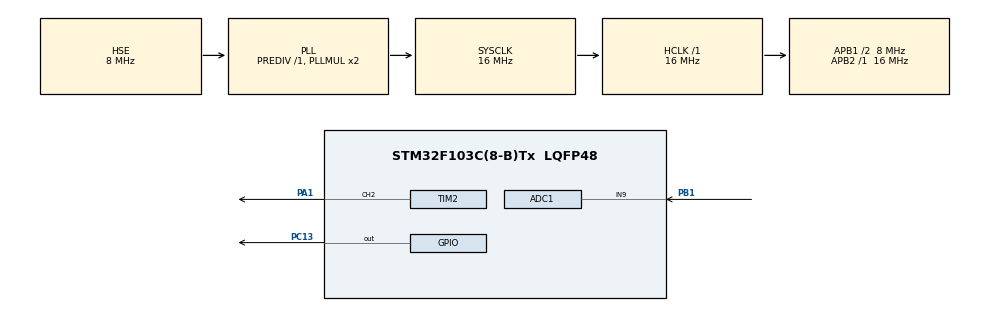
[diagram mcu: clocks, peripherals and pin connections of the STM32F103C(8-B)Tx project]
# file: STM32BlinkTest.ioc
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ADC1.Channel-1\#ChannelRegularConversion=ADC_CHANNEL_9
ADC1.ContinuousConvMode=ENABLE
ADC1.NbrOfConversionFlag=1
ADC1.Rank-1\#ChannelRegularConversion=1
ADC1.SamplingTime-1\#ChannelRegularConversion=ADC_SAMPLETIME_1CYCLE_5
ADC1.master=1
Mcu.Family=STM32F1
Mcu.Name=STM32F103C(8-B)Tx
Mcu.Package=LQFP48
NVIC.PriorityGroup=NVIC_PRIORITYGROUP_4
PA1.Signal=S_TIM2_CH2
PA13.Mode=Serial_Wire
PA13.Signal=SYS_JTMS-SWDIO
PA14.Mode=Serial_Wire
PA14.Signal=SYS_JTCK-SWCLK
PB1.Signal=ADCx_IN9
PC13-TAMPER-RTC.Signal=GPIO_Output
PD0-OSC_IN.Mode=HSE-External-Oscillator
PD0-OSC_IN.Signal=RCC_OSC_IN
PD1-OSC_OUT.Mode=HSE-External-Oscillator
PD1-OSC_OUT.Signal=RCC_OSC_OUT
ProjectManager.HeapSize=0x200
ProjectManager.StackSize=0x400
ProjectManager.TargetToolchain=STM32CubeIDE
RCC.AHBFreq_Value=16000000
RCC.APB1CLKDivider=RCC_HCLK_DIV2
RCC.APB1Freq_Value=8000000
RCC.APB1TimFreq_Value=16000000
RCC.APB2Freq_Value=16000000
RCC.APB2TimFreq_Value=16000000
RCC.HCLKFreq_Value=16000000
RCC.PLLSourceVirtual=RCC_PLLSOURCE_HSE
RCC.SYSCLKFreq_VALUE=16000000
RCC.SYSCLKSource=RCC_SYSCLKSOURCE_PLLCLK
RCC.USBFreq_Value=16000000
SH.ADCx_IN9.0=ADC1_IN9,IN9
SH.S_TIM2_CH2.0=TIM2_CH2,PWM Generation2 CH2
TIM2.Channel-PWM\ Generation2\ CH2=TIM_CHANNEL_2
TIM2.Period=625
TIM2.Prescaler=127
VP_TIM2_VS_ClockSourceINT.Mode=Internal
board=custom

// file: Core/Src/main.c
/* USER CODE BEGIN Header */
/**
  ******************************************************************************
  * @file           : main.c
  * @brief          : Main program body
  ******************************************************************************
  * @attention
  *
  * Copyright (c) 2023 STMicroelectronics.
  * All rights reserved.
  *
  * This software is licensed under terms that can be found in the LICENSE file
  * in the root directory of this software component.
  * If no LICENSE file comes with this software, it is provided AS-IS.
  *
  ******************************************************************************
  */
/* USER CODE END Header */
#include "main.h"
#include "adc.h"
#include "tim.h"
#include "gpio.h"

/* USER CODE BEGIN Includes */
//TIM_HandleTypeDef htim2;
/* USER CODE END Includes */

void SystemClock_Config(void);

int main(void)
{
  /* USER CODE BEGIN 1 */
//	int32_t CH_DC = 0;
  /* USER CODE END 1 */

  /* MCU Configuration--------------------------------------------------------*/

  /* Reset of all peripherals, Initializes the Flash interface and the Systick. */
  HAL_Init();

  /* Configure the system clock */
  SystemClock_Config();

  /* Initialize all configured peripherals */
  MX_GPIO_Init();
  MX_TIM2_Init();
  MX_ADC1_Init();
  /* USER CODE BEGIN 2 */
//  HAL_TIM_PWM_Start(&htim2, TIM_CHANNEL_2);
//  int32_t CH1_DC = 0;

  uint16_t readValue;
  HAL_ADC_Start(&hadc1);
  /* USER CODE END 2 */

  /* Infinite loop */
  while (1)
  {

    /* USER CODE BEGIN 3 */

//	  HAL_GPIO_TogglePin(GPIOC, GPIO_PIN_13);

//	  HAL_Delay(3000);
//	  HAL_GPIO_WritePin(GPIOB, GPIO_PIN_5, GPIO_PIN_SET);
//	  GPIO_PinState state = HAL_GPIO_ReadPin(GPIOB, GPIO_PIN_6);
//	  if (state) {
//		  HAL_GPIO_WritePin(GPIOC, GPIO_PIN_13, GPIO_PIN_SET);
//
//	  }
//	  else {
//		  HAL_GPIO_WritePin(GPIOC, GPIO_PIN_13, GPIO_PIN_RESET);
//	  }
//	  HAL_Delay(10);

//	  while(CH1_DC < 65535)
//	          {
//	              TIM2->CCR1 = CH1_DC;
//	              CH1_DC += 70;
//	              HAL_Delay(1);
//	          }
//	          while(CH1_DC > 0)
//	          {
//	              TIM2->CCR1 = CH1_DC;
//	              CH1_DC -= 70;
//	              HAL_Delay(1);
//	          }

	  /** pwm control
	  int x;
	  for (x=0; x<625;x++)
	  {
		  __HAL_TIM_SET_COMPARE(&htim2, TIM_CHANNEL_2, x);
		  HAL_Delay(3);
	  }

	  for (x=625; x>0;x--)
	  	  {
	  		  __HAL_TIM_SET_COMPARE(&htim2, TIM_CHANNEL_2, x);
	  		  HAL_Delay(3);
	  	  }

	  **/

	  HAL_ADC_PollForConversion(&hadc1, 1000);
	  readValue = HAL_ADC_GetValue(&hadc1);

  }
  /* USER CODE END 3 */
}

void SystemClock_Config(void)
{
  RCC_OscInitTypeDef RCC_OscInitStruct = {0};
  RCC_ClkInitTypeDef RCC_ClkInitStruct = {0};
  RCC_PeriphCLKInitTypeDef PeriphClkInit = {0};

  /** Initializes the RCC Oscillators according to the specified parameters
  * in the RCC_OscInitTypeDef structure.
  */
  RCC_OscInitStruct.OscillatorType = RCC_OSCILLATORTYPE_HSE;
  RCC_OscInitStruct.HSEState = RCC_HSE_ON;
  RCC_OscInitStruct.HSEPredivValue = RCC_HSE_PREDIV_DIV1;
  RCC_OscInitStruct.HSIState = RCC_HSI_ON;
  RCC_OscInitStruct.PLL.PLLState = RCC_PLL_ON;
  RCC_OscInitStruct.PLL.PLLSource = RCC_PLLSOURCE_HSE;
  RCC_OscInitStruct.PLL.PLLMUL = RCC_PLL_MUL2;
  if (HAL_RCC_OscConfig(&RCC_OscInitStruct) != HAL_OK)
  {
    Error_Handler();
  }

  /** Initializes the CPU, AHB and APB buses clocks
  */
  RCC_ClkInitStruct.ClockType = RCC_CLOCKTYPE_HCLK|RCC_CLOCKTYPE_SYSCLK
                              |RCC_CLOCKTYPE_PCLK1|RCC_CLOCKTYPE_PCLK2;
  RCC_ClkInitStruct.SYSCLKSource = RCC_SYSCLKSOURCE_PLLCLK;
  RCC_ClkInitStruct.AHBCLKDivider = RCC_SYSCLK_DIV1;
  RCC_ClkInitStruct.APB1CLKDivider = RCC_HCLK_DIV2;
  RCC_ClkInitStruct.APB2CLKDivider = RCC_HCLK_DIV1;

  if (HAL_RCC_ClockConfig(&RCC_ClkInitStruct, FLASH_LATENCY_0) != HAL_OK)
  {
    Error_Handler();
  }
  PeriphClkInit.PeriphClockSelection = RCC_PERIPHCLK_ADC;
  PeriphClkInit.AdcClockSelection = RCC_ADCPCLK2_DIV2;
  if (HAL_RCCEx_PeriphCLKConfig(&PeriphClkInit) != HAL_OK)
  {
    Error_Handler();
  }
}

void Error_Handler(void)
{
  __disable_irq();
  while (1)
  {
  }
}
